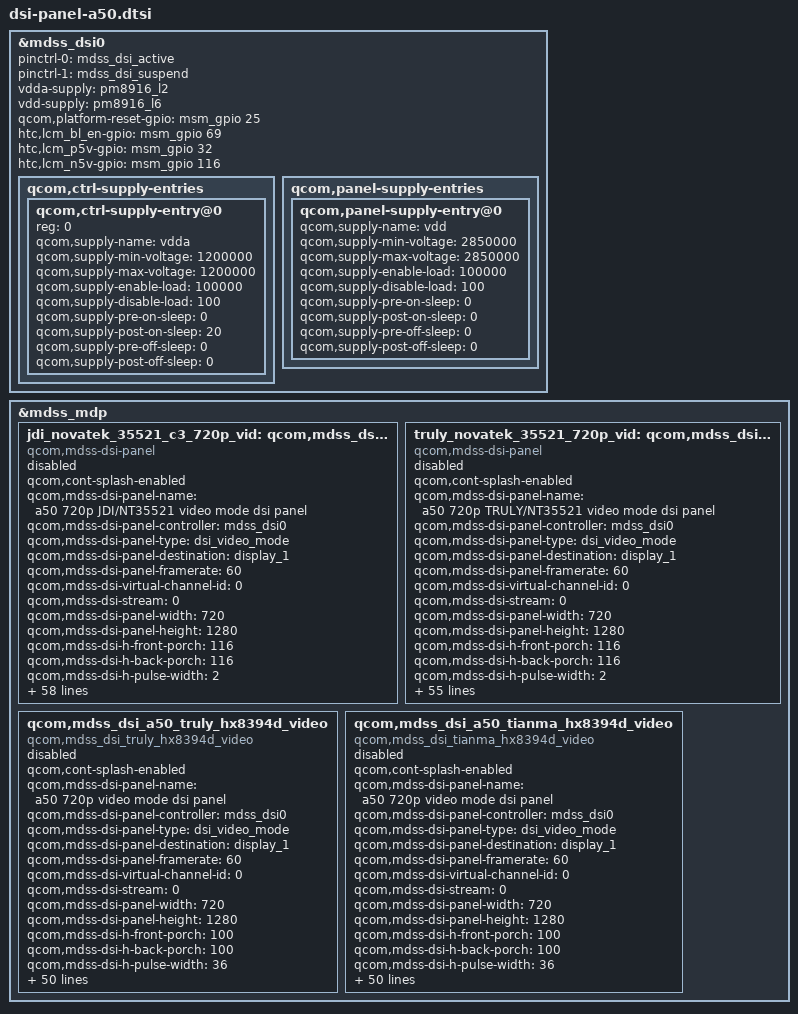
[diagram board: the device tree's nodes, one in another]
/*
&pmx_mdss {
	qcom,num-grp-pins = <4>;
	qcom,pins = <&gp 25>, <&gp 69>, <&gp 32>, <&gp 116>;
};
*/

&mdss_dsi0 {
	pinctrl-names = "mdss_default", "mdss_sleep";
	pinctrl-0 = <&mdss_dsi_active>;
	pinctrl-1 = <&mdss_dsi_suspend>;

	vdda-supply = <&pm8916_l2>;
	vdd-supply = <&pm8916_l6>;

	qcom,platform-reset-gpio = <&msm_gpio 25 0>;
	htc,lcm_bl_en-gpio = <&msm_gpio 69 0>;
	htc,lcm_p5v-gpio = <&msm_gpio 32 0>;
	htc,lcm_n5v-gpio = <&msm_gpio 116 0>;

	qcom,ctrl-supply-entries {
		#address-cells = <1>;
		#size-cells = <0>;

		qcom,ctrl-supply-entry@0 {
			reg = <0>;
			qcom,supply-name = "vdda";
			qcom,supply-min-voltage = <1200000>;
			qcom,supply-max-voltage = <1200000>;
			qcom,supply-enable-load = <100000>;
			qcom,supply-disable-load = <100>;
			qcom,supply-pre-on-sleep = <0>;
			qcom,supply-post-on-sleep = <20>;
			qcom,supply-pre-off-sleep = <0>;
			qcom,supply-post-off-sleep = <0>;
		};
	};

	qcom,panel-supply-entries {
		#address-cells = <1>;
		#size-cells = <0>;

		qcom,panel-supply-entry@0 {
			qcom,supply-name = "vdd";
			qcom,supply-min-voltage = <2850000>;
			qcom,supply-max-voltage = <2850000>;
			qcom,supply-enable-load = <100000>;
			qcom,supply-disable-load = <100>;
			qcom,supply-pre-on-sleep = <0>;
			qcom,supply-post-on-sleep = <0>;
			qcom,supply-pre-off-sleep = <0>;
			qcom,supply-post-off-sleep = <0>;
		};
	};
};

&mdss_mdp {
	jdi_novatek_35521_c3_720p_vid:qcom,mdss_dsi_jdi_novatek_35521_c3_720p_video {
		compatible = "qcom,mdss-dsi-panel";
		status = "disable";
		qcom,cont-splash-enabled;
		qcom,mdss-dsi-panel-name = "a50 720p JDI/NT35521 video mode dsi panel";
		qcom,mdss-dsi-panel-controller = <&mdss_dsi0>;
		qcom,mdss-dsi-panel-type = "dsi_video_mode";
		qcom,mdss-dsi-panel-destination = "display_1";
		qcom,mdss-dsi-panel-framerate = <60>;
		qcom,mdss-dsi-virtual-channel-id = <0>;
		qcom,mdss-dsi-stream = <0>;
		qcom,mdss-dsi-panel-width = <720>;
		qcom,mdss-dsi-panel-height = <1280>;
		qcom,mdss-dsi-h-front-porch = <116>;
		qcom,mdss-dsi-h-back-porch = <116>;
		qcom,mdss-dsi-h-pulse-width = <2>;
		qcom,mdss-dsi-h-sync-skew = <0>;
		qcom,mdss-dsi-v-back-porch = <13>;
		qcom,mdss-dsi-v-front-porch = <11>;
		qcom,mdss-dsi-v-pulse-width = <2>;
		qcom,mdss-dsi-h-left-border = <0>;
		qcom,mdss-dsi-h-right-border = <0>;
		qcom,mdss-dsi-v-top-border = <0>;
		qcom,mdss-dsi-v-bottom-border = <0>;
		qcom,mdss-dsi-bpp = <24>;
		qcom,mdss-dsi-color-order = "rgb_swap_rgb";
		qcom,mdss-dsi-underflow-color = <0xff>;
		qcom,mdss-dsi-border-color = <0>;
		qcom,mdss-dsi-on-command = [
			15 01 00 00 00 00 02 BB 03 /* MIPI VIDEO mode */
			05 01 00 00 8C 00 02 11 00 /* LCD Sleep out command */
			15 01 00 00 00 00 02 53 2C /* Backlight control */
			29 01 00 00 00 00 06 F0 55 AA 52 08 00 /* CABC PWM Setting */
			15 01 00 00 00 00 02 d3 00 /* CABC PWM Setting */
			29 01 00 00 00 00 03 d6 44 44 /* CABC PWM Setting */
			29 01 00 00 00 00 0B E8 FF FE F8 EE D7 BA A8 82 68 66 /* CABC Moving Mode */
			29 01 00 00 00 00 05 FF AA 55 A5 80 /* CABC Moving Mode */
			15 01 00 00 00 00 02 6F 10 /* CABC Moving Mode */
			15 01 00 00 00 00 02 F5 70 /* CABC Moving Mode */
			29 01 00 00 00 00 0B E7 FF FF FA FA F8 EB DC D4 B5 B3 /* CABC Still Mode */
			29 01 00 00 00 00 12 D1 00 05 10 17 22 26 29 29 29 26 23 17 12 06 02 01 00 /* Vivid Color */
			29 01 00 00 00 00 11 CC 41 36 87 00 00 00 00 00 00 00 00 00 00 00 00 05 /* Vivid Color */
			29 01 00 00 00 00 0D D7 30 30 30 28 00 00 00 00 00 00 00 00 /* Vivid Color */
			29 01 00 00 00 00 0D D8 00 00 00 00 00 00 00 00 00 28 30 30 /* Vivid Color */
			15 01 00 00 00 00 02 55 82 /* CABC control 01: CABC on*/
			15 01 00 00 00 00 02 5E 22];
		qcom,mdss-dsi-off-command = [
			15 01 00 00 00 00 02 53 00 /* Backlight control */
			15 01 00 00 00 00 02 55 00 /* CABC control 00: CABC off*/
			05 01 00 00 14 00 02 28 00 /* display_off */
			05 01 00 00 8C 00 02 10 00 /* Sleep in */];
		qcom,mdss-dsi-on-command-state = "dsi_lp_mode";
		qcom,mdss-dsi-off-command-state = "dsi_hs_mode";
		qcom,mdss-dsi-h-sync-pulse = <0>;
		qcom,mdss-dsi-traffic-mode = "non_burst_sync_event";
		qcom,mdss-dsi-bllp-eof-power-mode;
		qcom,mdss-dsi-lane-map = "lane_map_0123";
		qcom,mdss-dsi-bllp-power-mode;
		qcom,mdss-dsi-lane-0-state;
		qcom,mdss-dsi-lane-1-state;
		qcom,mdss-dsi-lane-2-state;
		qcom,mdss-dsi-panel-timings =  [37 27 20 01 3c 39 21
					29 32 03 04 00];
		qcom,mdss-dsi-t-clk-post = <0x1f>;
		qcom,mdss-dsi-t-clk-pre = <0x39>;
		qcom,mdss-dsi-bl-min-level = <1>;
		qcom,mdss-dsi-bl-max-level = <255>;
		qcom,mdss-dsi-dma-trigger = "trigger_sw";
		qcom,mdss-dsi-mdp-trigger = "none";
		qcom,mdss-dsi-bl-pmic-control-type = "bl_ctrl_dcs";

		qcom,display-on-cmds = [05 01 00 00 00 00 02 29 00 /* LCD Display on */];
		htc,cabc-off-cmds = [39 01 00 00 00 00 02 55 00];
		htc,cabc-ui-cmds = [39 01 00 00 00 00 02 55 82];
		htc,cabc-video-cmds = [39 01 00 00 00 00 02 55 83];
		htc,dimming-on-cmds = [39 01 00 00 00 00 02 53 2C];
		qcom,mdss-dsi-default-command-state = "dsi_hs_mode";
		qcom,mdss-pan-physical-width-dimension = <68>;
		qcom,mdss-pan-physical-height-dimension = <121>;
		qcom,mdss-shrink-pwm = <7 61 255>;
		qcom,mdss-dsi-lp11-init;
		htc,mdss-camera-blk = <194>;
		htc,mdp-pcc-r = <0x8000>;
		htc,mdp-pcc-g = <0x7B8D>;
		htc,mdp-pcc-b = <0x7BAB>;
		htc,panel-id=<1>;
		htc,skip-frame;
	};
	truly_novatek_35521_720p_vid:qcom,mdss_dsi_truly_novatek_35521_720p_video {
		compatible = "qcom,mdss-dsi-panel";
		status = "disable";
		qcom,cont-splash-enabled;
		qcom,mdss-dsi-panel-name = "a50 720p TRULY/NT35521 video mode dsi panel";
		qcom,mdss-dsi-panel-controller = <&mdss_dsi0>;
		qcom,mdss-dsi-panel-type = "dsi_video_mode";
		qcom,mdss-dsi-panel-destination = "display_1";
		qcom,mdss-dsi-panel-framerate = <60>;
		qcom,mdss-dsi-virtual-channel-id = <0>;
		qcom,mdss-dsi-stream = <0>;
		qcom,mdss-dsi-panel-width = <720>;
		qcom,mdss-dsi-panel-height = <1280>;
		qcom,mdss-dsi-h-front-porch = <116>;
		qcom,mdss-dsi-h-back-porch = <116>;
		qcom,mdss-dsi-h-pulse-width = <2>;
		qcom,mdss-dsi-h-sync-skew = <0>;
		qcom,mdss-dsi-v-back-porch = <13>;
		qcom,mdss-dsi-v-front-porch = <11>;
		qcom,mdss-dsi-v-pulse-width = <2>;
		qcom,mdss-dsi-h-left-border = <0>;
		qcom,mdss-dsi-h-right-border = <0>;
		qcom,mdss-dsi-v-top-border = <0>;
		qcom,mdss-dsi-v-bottom-border = <0>;
		qcom,mdss-dsi-bpp = <24>;
		qcom,mdss-dsi-color-order = "rgb_swap_rgb";
		qcom,mdss-dsi-underflow-color = <0xff>;
		qcom,mdss-dsi-border-color = <0>;
		qcom,mdss-dsi-on-command = [
			39 00 00 00 00 00 05 FF AA 55 A5 80
			39 00 00 00 00 00 06 F0 55 AA 52 08 00
			39 00 00 00 00 00 03 B1 68 21
			39 00 00 00 00 00 02 B5 C8
			39 00 00 00 00 00 02 B6 02

			39 00 00 00 00 00 02 C8 83
			39 00 00 00 00 00 06 BD 01 A0 10 08 01
			39 00 00 00 00 00 03 BB 74 44
			39 00 00 00 00 00 02 BC 00
			39 00 00 00 00 00 02 6F 17
			39 00 00 00 00 00 02 F4 60
			39 00 00 00 00 00 04 D9 00 01 00

			39 00 00 00 00 00 06 F0 55 AA 52 08 01
			39 00 00 00 00 00 03 B0 09 09
			39 00 00 00 00 00 03 B1 09 09

			39 00 00 00 00 00 03 B3 23 23
			39 00 00 00 00 00 03 B4 20 20
			39 00 00 00 00 00 03 B9 35 35
			39 00 00 00 00 00 03 BA 25 25

			39 00 00 00 00 00 03 BC 8C 00
			39 00 00 00 00 00 03 BD 8C 00
			39 00 00 00 00 00 02 CA 00
			39 00 00 00 00 00 02 C0 04

			39 00 00 00 00 00 06 F0 55 AA 52 08 02
			39 00 00 00 00 00 02 EE 03
			39 00 00 00 00 00 11 B0 00 3C 00 55 00 68 00 7B 00 8B 00 A7 00 C2 00 EE
			39 00 00 00 00 00 11 B1 01 0E 01 46 01 73 01 B8 01 F3 01 F4 02 2D 02 6E
			39 00 00 00 00 00 11 B2 02 98 02 D1 02 F7 03 29 03 4C 03 64 03 90 03 E3
			39 00 00 00 00 00 05 B3 03 FE 03 FE

			39 00 00 00 00 00 11 B4 00 70 00 76 00 87 00 96 00 A2 00 BD 00 D3 00 F8
			39 00 00 00 00 00 11 B5 01 17 01 4A 01 75 01 BA 01 F4 01 F6 02 2E 02 6E
			39 00 00 00 00 00 11 B6 02 98 02 D0 02 F7 03 2A 03 4D 03 66 03 91 03 FB
			39 00 00 00 00 00 05 B7 03 FE 03 FE
			39 00 00 00 00 00 11 B8 00 01 00 02 00 21 00 3C 00 50 00 75 00 93 00 C5
			39 00 00 00 00 00 11 B9 00 ED 01 2A 01 5C 01 A8 01 E7 01 E8 02 23 02 65
			39 00 00 00 00 00 11 BA 02 8E 02 C8 02 F0 03 2B 03 61 03 F9 03 FA 03 FC
			39 00 00 00 00 00 05 BB 03 FD 03 FE

			39 00 00 00 00 00 06 F0 55 AA 52 08 03
			39 00 00 00 00 00 03 B0 22 00
			39 00 00 00 00 00 03 B1 22 00

			39 00 00 00 00 00 06 B2 05 00 60 00 00
			39 00 00 00 00 00 06 B3 05 00 60 00 00
			39 00 00 00 00 00 06 B4 05 00 60 00 00
			39 00 00 00 00 00 06 B5 05 00 60 00 00

			39 00 00 00 00 00 06 BA 53 00 60 00 00
			39 00 00 00 00 00 06 BB 53 00 60 00 00
			39 00 00 00 00 00 06 BC 53 00 60 00 00
			39 00 00 00 00 00 06 BD 53 00 60 00 00

			39 00 00 00 00 00 05 C0 00 34 00 00
			39 00 00 00 00 00 05 C1 00 00 34 00
			39 00 00 00 00 00 05 C2 00 00 34 00
			39 00 00 00 00 00 05 C3 00 00 34 00
			39 00 00 00 00 00 02 C4 60
			39 00 00 00 00 00 02 C5 C0
			39 00 00 00 00 00 02 C6 00
			39 00 00 00 00 00 02 C7 00

			39 00 00 00 00 00 06 F0 55 AA 52 08 05

			39 00 00 00 00 00 03 B0 17 06
			39 00 00 00 00 00 03 B1 17 06
			39 00 00 00 00 00 03 B2 17 06
			39 00 00 00 00 00 03 B3 17 06
			39 00 00 00 00 00 03 B4 17 06
			39 00 00 00 00 00 03 B5 17 06
			39 00 00 00 00 00 03 B6 17 06
			39 00 00 00 00 00 03 B7 17 06
			39 00 00 00 00 00 02 B8 00
			39 00 00 00 00 00 03 B9 00 03
			39 00 00 00 00 00 03 BA 00 00
			39 00 00 00 00 00 03 BB 02 03
			39 00 00 00 00 00 03 BC 02 03
			39 00 00 00 00 00 06 BD 03 03 00 03 03
			39 00 00 00 00 00 02 C0 0B
			39 00 00 00 00 00 02 C1 09
			39 00 00 00 00 00 02 C2 A6
			39 00 00 00 00 00 02 C3 05
			39 00 00 00 00 00 02 C4 00
			39 00 00 00 00 00 02 C5 02
			39 00 00 00 00 00 02 C6 22
			39 00 00 00 00 00 02 C7 03
			39 00 00 00 00 00 03 C8 07 20
			39 00 00 00 00 00 03 C9 03 20
			39 00 00 00 00 00 03 CA 01 60
			39 00 00 00 00 00 03 CB 01 60
			39 00 00 00 00 00 04 CC 00 00 02
			39 00 00 00 00 00 04 CD 00 00 02
			39 00 00 00 00 00 04 CE 00 00 02
			39 00 00 00 00 00 04 CF 00 00 02

			39 00 00 00 00 00 06 D1 00 05 01 07 10
			39 00 00 00 00 00 06 D2 10 05 05 03 10
			39 00 00 00 00 00 06 D3 20 00 43 07 10
			39 00 00 00 00 00 06 D4 30 00 43 07 10
			39 00 00 00 00 00 08 D0 00 00 00 00 00 00 00
			39 00 00 00 00 00 0C D5 00 00 00 00 00 00 00 00 00 00 00
			39 00 00 00 00 00 0C D6 00 00 00 00 00 00 00 00 00 00 00
			39 00 00 00 00 00 0C D7 00 00 00 00 00 00 00 00 00 00 00
			39 00 00 00 00 00 06 D8 00 00 00 00 00
			39 00 00 00 00 00 02 E5 06
			39 00 00 00 00 00 02 E6 06
			39 00 00 00 00 00 02 E7 00
			39 00 00 00 00 00 02 E8 06
			39 00 00 00 00 00 02 E9 06
			39 00 00 00 00 00 02 EA 06
			39 00 00 00 00 00 02 EB 00
			39 00 00 00 00 00 02 EC 00
			39 00 00 00 00 00 02 ED 30

			39 00 00 00 00 00 06 F0 55 AA 52 08 06

			39 00 00 00 00 00 03 B0 31 31
			39 00 00 00 00 00 03 B1 31 31
			39 00 00 00 00 00 03 B2 2D 2E
			39 00 00 00 00 00 03 B3 31 34
			39 00 00 00 00 00 03 B4 29 2A
			39 00 00 00 00 00 03 B5 12 10
			39 00 00 00 00 00 03 B6 18 16
			39 00 00 00 00 00 03 B7 00 02
			39 00 00 00 00 00 03 B8 08 31
			39 00 00 00 00 00 03 B9 31 31

			39 00 00 00 00 00 03 BA 31 31
			39 00 00 00 00 00 03 BB 31 08
			39 00 00 00 00 00 03 BC 03 01
			39 00 00 00 00 00 03 BD 17 19
			39 00 00 00 00 00 03 BE 11 13
			39 00 00 00 00 00 03 BF 2A 29
			39 00 00 00 00 00 03 C0 34 31
			39 00 00 00 00 00 03 C1 2E 2D
			39 00 00 00 00 00 03 C2 31 31
			39 00 00 00 00 00 03 C3 31 31

			39 00 00 00 00 00 03 C4 31 31
			39 00 00 00 00 00 03 C5 31 31
			39 00 00 00 00 00 03 C6 2E 2D
			39 00 00 00 00 00 03 C7 31 34
			39 00 00 00 00 00 03 C8 29 2A
			39 00 00 00 00 00 03 C9 17 19
			39 00 00 00 00 00 03 CA 11 13
			39 00 00 00 00 00 03 CB 03 01
			39 00 00 00 00 00 03 CC 08 31
			39 00 00 00 00 00 03 CD 31 31

			39 00 00 00 00 00 03 CE 31 31
			39 00 00 00 00 00 03 CF 31 08
			39 00 00 00 00 00 03 D0 00 02
			39 00 00 00 00 00 03 D1 12 10
			39 00 00 00 00 00 03 D2 18 16
			39 00 00 00 00 00 03 D3 2A 29
			39 00 00 00 00 00 03 D4 34 31
			39 00 00 00 00 00 03 D5 2D 2E
			39 00 00 00 00 00 03 D6 31 31
			39 00 00 00 00 00 03 D7 31 31

			39 00 00 00 00 00 06 D8 00 00 00 00 00
			39 00 00 00 00 00 06 D9 00 00 00 00 00
			39 00 00 00 00 00 06 F0 55 AA 52 08 00

			39 00 00 00 00 00 06 F0 55 AA 52 08 00 /*CABC PWM setting */
			39 00 00 00 00 00 02 D3 00 /*CABC PWM setting */
			39 00 00 00 00 00 03 D6 44 44 /*CABC PWM setting */
			39 00 00 00 00 00 0b E8 FF FE F8 EE D7 BA A8 82 68 66 /*Moving mode*/
			39 00 00 00 00 00 05 FF AA 55 A5 80 /*Moving mode*/
			39 00 00 00 00 00 02 6F 10 /*Moving mode*/
			39 00 00 00 00 00 02 F5 70 /*Moving mode*/
			39 00 00 00 00 00 0b E7 FF FF FA FA F8 EB DC D4 B5 B3 /*CABC STILL mode setting*/
			39 00 00 00 00 00 12 D1 00 05 10 17 22 26 29 29 29 26 23 17 12 06 02 01 00 /*IE vivid color */
			39 00 00 00 00 00 11 CC 41 36 87 00 00 00 00 00 00 00 00 00 00 00 00 05 /*IE vivid color */
			39 00 00 00 00 00 0d D7 30 30 30 28 00 00 00 00 00 00 00 00 /*IE vivid color */
			39 00 00 00 00 00 0d D8 00 00 00 00 00 00 00 00 00 28 30 30 /*IE vivid color */
			39 00 00 00 00 00 02 5E 22 /*IE vivid color */

			39 00 00 00 00 00 02 53 24
			39 00 00 00 00 00 02 55 82 /*CABC ON - still mode */
			05 01 00 00 78 00 02 11 00
		];
		qcom,mdss-dsi-off-command = [
			15 01 00 00 00 00 02 53 00 /* Backlight control */
			15 01 00 00 00 00 02 55 00 /* CABC control 00: CABC off*/
			05 01 00 00 14 00 02 28 00 /* display_off */
			05 01 00 00 78 00 02 10 00 /* Sleep in */];
		qcom,mdss-dsi-on-command-state = "dsi_lp_mode";
		qcom,mdss-dsi-off-command-state = "dsi_hs_mode";
		qcom,mdss-dsi-h-sync-pulse = <0>;
		qcom,mdss-dsi-traffic-mode = "non_burst_sync_event";
		qcom,mdss-dsi-bllp-eof-power-mode;
		qcom,mdss-dsi-lane-map = "lane_map_0123";
		qcom,mdss-dsi-bllp-power-mode;
		qcom,mdss-dsi-lane-0-state;
		qcom,mdss-dsi-lane-1-state;
		qcom,mdss-dsi-lane-2-state;
		qcom,mdss-dsi-panel-timings =  [37 27 20 01 3c 39 21
					29 32 03 04 00];
		qcom,mdss-dsi-t-clk-post = <0x1f>;
		qcom,mdss-dsi-t-clk-pre = <0x39>;
		qcom,mdss-dsi-bl-min-level = <1>;
		qcom,mdss-dsi-bl-max-level = <255>;
		qcom,mdss-dsi-dma-trigger = "trigger_sw";
		qcom,mdss-dsi-mdp-trigger = "none";
		qcom,mdss-dsi-bl-pmic-control-type = "bl_ctrl_dcs";

		qcom,display-on-cmds = [05 01 00 00 14 00 02 29 00 /* LCD Display on */];
		htc,cabc-off-cmds = [39 01 00 00 00 00 02 55 00];
		htc,cabc-ui-cmds = [39 01 00 00 00 00 02 55 82];
		htc,cabc-video-cmds = [39 01 00 00 00 00 02 55 83];
		htc,dimming-on-cmds = [39 01 00 00 00 00 02 53 2C];
		qcom,mdss-dsi-default-command-state = "dsi_hs_mode";
		qcom,mdss-pan-physical-width-dimension = <68>;
		qcom,mdss-pan-physical-height-dimension = <121>;
		qcom,mdss-shrink-pwm = <6 88 255>;
		qcom,mdss-dsi-lp11-init;
		htc,mdss-camera-blk = <189>;
		htc,panel-id=<2>;
		htc,skip-frame;
	};
	qcom,mdss_dsi_a50_truly_hx8394d_video {
		compatible = "qcom,mdss_dsi_truly_hx8394d_video";
		status = "disable";
		qcom,cont-splash-enabled;
		qcom,mdss-dsi-panel-name = "a50 720p video mode dsi panel";
		qcom,mdss-dsi-panel-controller = <&mdss_dsi0>;
		qcom,mdss-dsi-panel-type = "dsi_video_mode";
		qcom,mdss-dsi-panel-destination = "display_1";
		qcom,mdss-dsi-panel-framerate = <60>;
		qcom,mdss-dsi-virtual-channel-id = <0>;
		qcom,mdss-dsi-stream = <0>;
		qcom,mdss-dsi-panel-width = <720>;
		qcom,mdss-dsi-panel-height = <1280>;
		qcom,mdss-dsi-h-front-porch = <100>;
		qcom,mdss-dsi-h-back-porch = <100>;
		qcom,mdss-dsi-h-pulse-width = <36>;
		qcom,mdss-dsi-h-sync-skew = <0>;
		qcom,mdss-dsi-v-back-porch = <12>;
		qcom,mdss-dsi-v-front-porch = <15>;
		qcom,mdss-dsi-v-pulse-width = <4>;
		qcom,mdss-dsi-h-left-border = <0>;
		qcom,mdss-dsi-h-right-border = <0>;
		qcom,mdss-dsi-v-top-border = <0>;
		qcom,mdss-dsi-v-bottom-border = <0>;
		qcom,mdss-dsi-bpp = <24>;
		qcom,mdss-dsi-color-order = "rgb_swap_rgb";
		qcom,mdss-dsi-underflow-color = <0xff>;
		qcom,mdss-dsi-border-color = <0>;
		qcom,mdss-dsi-on-command = [
				39 01 00 00 00 00 04 B9 FF 83 94
				39 01 00 00 00 00 03 BA 32 83
				39 01 00 00 00 00 10 B1 6C 11 11 24 04 11 F1 80 EA 96 23 80 C0 D2 58
				39 01 00 00 00 00 0C B2 00 64 10 07 32 1C 08 08 1C 4D 00
				39 01 00 00 00 00 02 BC 07
				39 01 00 00 00 00 0D B4 00 FF 40 50 40 50 40 50 01 6A 01 6A
				39 01 00 00 00 00 1F D3 00 06 00 40 07 00 00 32 10 08 00 08 52 15 0F 05 0F 32 10 00 00 00 47 44 0C 0C 47 0C 0C 47
				39 01 00 00 00 00 2D D5 20 21 00 01 02 03 04 05 06 07 18 18 18 18 18 18 18 18 18 18 18 18 18 18 18 18 18 18 18 18 18 18 18 18 18 18 18 18 19 19 18 18 24 25
				39 01 00 00 00 00 2D D6 24 25 07 06 05 04 03 02 01 00 18 18 18 18 18 18 18 18 58 58 18 18 18 18 18 18 18 18 18 18 18 18 18 18 18 18 18 18 18 18 19 19 20 21
				39 01 00 00 00 00 2B E0 00 01 05 31 38 3F 15 3D 06 09 0B 16 0E 12 15 13 14 07 11 13 18 00 01 05 31 37 3F 14 3E 06 09 0B 17 0F 12 15 13 14 07 11 12 16
				39 01 00 00 14 00 02 BD 00
				39 01 00 00 00 00 2C C1 01 00 08 10 17 1F 26 2E 35 3D 44 4B 53 5B 62 6A 72 79 81 89 91 99 A1 A9 B1 B9 C1 CA D2 DA E3 EC F5 FF 16 27 FB 29 D5 45 22 FF C0
				39 01 00 00 14 00 02 BD 01
				39 01 00 00 00 00 2B C1 00 08 10 17 1F 26 2E 35 3D 44 4B 53 5B 62 6A 72 79 81 89 91 99 A1 A9 B1 B9 C1 CA D2 DA E3 EC F5 FF 16 27 FB 29 D5 45 22 FF C0
				39 01 00 00 14 00 02 BD 02
				39 01 00 00 00 00 2B C1 00 08 10 17 1F 26 2E 35 3D 44 4B 53 5B 62 6A 72 79 81 89 91 99 A1 A9 B1 B9 C1 CA D2 DA E3 EC F5 FF 16 27 FB 29 D5 45 22 FF C0
				39 01 00 00 00 00 02 CC 09
				39 01 00 00 00 00 03 C0 30 14
				39 01 00 00 00 00 05 C7 00 C0 40 C0
				39 01 00 00 05 00 02 55 11
				39 01 00 00 0A 00 02 53 24
				05 01 00 01 96 00 02 11 00
				05 01 00 01 0A 00 02 29 00
		];
		qcom,mdss-dsi-off-command = [
			05 01 00 00 01 00 02 28 00 /* display_off */
			05 01 00 00 78 00 02 10 00 /* Sleep in */];
		qcom,mdss-dsi-on-command-state = "dsi_lp_mode";
		qcom,mdss-dsi-off-command-state = "dsi_hs_mode";
		qcom,mdss-dsi-h-sync-pulse = <0>;
		qcom,mdss-dsi-traffic-mode = "non_burst_sync_event";
		qcom,mdss-dsi-bllp-eof-power-mode;
		qcom,mdss-dsi-lane-map = "lane_map_0123";
		qcom,mdss-dsi-bllp-power-mode;
		qcom,mdss-dsi-lane-0-state;
		qcom,mdss-dsi-lane-1-state;
		qcom,mdss-dsi-lane-2-state;
		qcom,mdss-dsi-panel-timings = [38 2F 25 00 43 3D 2A 31 3C 03 04 00];
		qcom,mdss-dsi-t-clk-post = <0x1f>;
		qcom,mdss-dsi-t-clk-pre = <0x39>;
		qcom,mdss-dsi-bl-min-level = <1>;
		qcom,mdss-dsi-bl-max-level = <255>;
		qcom,mdss-dsi-dma-trigger = "trigger_sw";
		qcom,mdss-dsi-mdp-trigger = "none";
		qcom,mdss-dsi-bl-pmic-control-type = "bl_ctrl_dcs";
		qcom,display-on-cmds = [05 01 00 00 28 00 02 29 00 /* LCD Display on */];
		qcom,mdss-dsi-default-command-state = "dsi_hs_mode";
		qcom,mdss-pan-physical-width-dimension = <68>;
		qcom,mdss-pan-physical-height-dimension = <121>;
		qcom,mdss-shrink-pwm = <6 88 255>;
		qcom,mdss-dsi-lp11-init;
		htc,dimming-on-cmds = [39 01 00 00 00 00 02 53 2C];
		htc,mdss-camera-blk = <189>;
		htc,panel-id = <3>;
		htc,skip-frame;
	};
	qcom,mdss_dsi_a50_tianma_hx8394d_video {
		compatible = "qcom,mdss_dsi_tianma_hx8394d_video";
		status = "disable";
		qcom,cont-splash-enabled;
		qcom,mdss-dsi-panel-name = "a50 720p video mode dsi panel";
		qcom,mdss-dsi-panel-controller = <&mdss_dsi0>;
		qcom,mdss-dsi-panel-type = "dsi_video_mode";
		qcom,mdss-dsi-panel-destination = "display_1";
		qcom,mdss-dsi-panel-framerate = <60>;
		qcom,mdss-dsi-virtual-channel-id = <0>;
		qcom,mdss-dsi-stream = <0>;
		qcom,mdss-dsi-panel-width = <720>;
		qcom,mdss-dsi-panel-height = <1280>;
		qcom,mdss-dsi-h-front-porch = <100>;
		qcom,mdss-dsi-h-back-porch = <100>;
		qcom,mdss-dsi-h-pulse-width = <36>;
		qcom,mdss-dsi-h-sync-skew = <0>;
		qcom,mdss-dsi-v-back-porch = <12>;
		qcom,mdss-dsi-v-front-porch = <15>;
		qcom,mdss-dsi-v-pulse-width = <4>;
		qcom,mdss-dsi-h-left-border = <0>;
		qcom,mdss-dsi-h-right-border = <0>;
		qcom,mdss-dsi-v-top-border = <0>;
		qcom,mdss-dsi-v-bottom-border = <0>;
		qcom,mdss-dsi-bpp = <24>;
		qcom,mdss-dsi-color-order = "rgb_swap_rgb";
		qcom,mdss-dsi-underflow-color = <0xff>;
		qcom,mdss-dsi-border-color = <0>;
		qcom,mdss-dsi-on-command = [
			39 01 00 00 00 00 04 B9 FF 83 94
			39 01 00 00 00 00 03 BA 32 83
			39 01 00 00 00 00 10 B1 6C 0F 0F 37 04 11 F1 80 DE 94 23 80 C0 D2 18
			39 01 00 00 00 00 0C B2 00 64 0E 0D 32 23 08 08 1C 4D 00
			39 01 00 00 01 00 02 BC 07
			39 01 00 00 00 00 0D B4 00 FF 03 5A 03 5A 03 5A 01 6A 01 6A
			39 01 00 00 00 00 04 BF 41 0E 01
			39 01 00 00 00 00 26 D3 00 07 00 00 00 10 00 32 10 05 00 05 32 10 00 00 00 32 10 00 00 00 36 03 09 09 37 00 00 37 00 00 00 00 0A 00 01
			39 01 00 00 00 00 2D D5 02 03 00 01 06 07 04 05 20 21 22 23 18 18 18 18 18 18 18 18 18 18 18 18 18 18 18 18 18 18 18 18 18 18 18 18 18 18 24 25 18 18 19 19
			39 01 00 00 00 00 2D D6 05 04 07 06 01 00 03 02 23 22 21 20 18 18 18 18 18 18 58 58 18 18 18 18 18 18 18 18 18 18 18 18 18 18 18 18 18 18 25 24 19 19 18 18
			39 01 00 00 00 00 2B E0 02 15 17 24 29 33 23 3E 08 0B 0D 16 0E 12 15 13 14 08 12 16 19 02 15 17 24 29 33 23 3E 08 0B 0D 16 0E 12 15 13 14 08 12 16 19
			39 01 00 00 00 00 02 CC 09
			39 01 00 00 00 00 03 C0 30 14
			39 01 00 00 00 00 05 C7 00 C0 40 C0
			39 01 00 00 05 00 02 55 11
			39 01 00 00 0A 00 02 53 24
			39 01 00 00 78 00 02 11 00
			39 01 00 00 0A 00 02 29 00
		];
		qcom,mdss-dsi-off-command = [
			05 01 00 00 01 00 02 28 00 /* display_off */
			05 01 00 00 78 00 02 10 00 /* Sleep in */];
		qcom,mdss-dsi-on-command-state = "dsi_lp_mode";
		qcom,mdss-dsi-off-command-state = "dsi_hs_mode";
		qcom,mdss-dsi-h-sync-pulse = <0>;
		qcom,mdss-dsi-traffic-mode = "non_burst_sync_event";
		qcom,mdss-dsi-bllp-eof-power-mode;
		qcom,mdss-dsi-lane-map = "lane_map_0123";
		qcom,mdss-dsi-bllp-power-mode;
		qcom,mdss-dsi-lane-0-state;
		qcom,mdss-dsi-lane-1-state;
		qcom,mdss-dsi-lane-2-state;
		qcom,mdss-dsi-panel-timings = [38 2F 25 00 43 3D 2A 31 3C 03 04 00];
		qcom,mdss-dsi-t-clk-post = <0x1f>;
		qcom,mdss-dsi-t-clk-pre = <0x39>;
		qcom,mdss-dsi-bl-min-level = <1>;
		qcom,mdss-dsi-bl-max-level = <255>;
		qcom,mdss-dsi-dma-trigger = "trigger_sw";
		qcom,mdss-dsi-mdp-trigger = "none";
		qcom,mdss-dsi-bl-pmic-control-type = "bl_ctrl_dcs";
		qcom,display-on-cmds = [05 01 00 00 28 00 02 29 00 /* LCD Display on */];
		qcom,mdss-dsi-default-command-state = "dsi_hs_mode";
		qcom,mdss-pan-physical-width-dimension = <68>;
		qcom,mdss-pan-physical-height-dimension = <121>;
		qcom,mdss-shrink-pwm = <6 88 255>;
		qcom,mdss-dsi-lp11-init;
		htc,dimming-on-cmds = [39 01 00 00 00 00 02 53 2C];
		htc,mdss-camera-blk = <189>;
		htc,panel-id = <4>;
		htc,skip-frame;
	};
};
